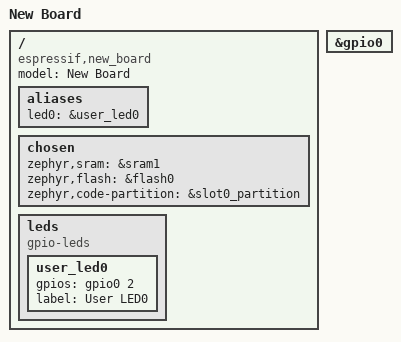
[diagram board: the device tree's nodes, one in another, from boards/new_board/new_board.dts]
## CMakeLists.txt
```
cmake_minimum_required(VERSION 3.20.0)

list(APPEND BOARD_ROOT ${CMAKE_CURRENT_SOURCE_DIR})
find_package(Zephyr REQUIRED)
project(my_zephyr_app)

target_sources(app PRIVATE src/main.cpp)
target_include_directories(app PRIVATE ${CMAKE_CURRENT_SOURCE_DIR}/drivers/our_driver)

add_subdirectory(drivers/our_driver)
```

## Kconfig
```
menuconfig LED_SUBSYSTEM
    bool "LED Subsystem"

    help
      Enable LED subsystem support.

if LED_SUBSYSTEM
    choice 
        prompt "LED Blink sleep"
        default BLINK_SLEEP_1000MS
    
    config BLINK_SLEEP_1000MS
        bool "1s Medium"
    
    config BLINK_SLEEP_250MS
        bool "250ms Very Fast"
    
    config BLINK_SLEEP_2000MS
        bool "2s Slow"
    
    config BLINK_SLEEP_500MS
        bool "500ms Fast"
    
    endchoice

    config BLINK_SLEEP_TIME_MS
        int
        default 1000 if BLINK_SLEEP_1000MS
        default 250 if BLINK_SLEEP_250MS
        default 2000 if BLINK_SLEEP_2000MS
        default 500 if BLINK_SLEEP_500MS
    
menuconfig ADVANCED_LED_SETTINGS
    bool "Advanced LED Settings"

if ADVANCED_LED_SETTINGS    
    config LED_BRIGHTNESS
            int "LED Brightness (0-100)"
            default 100
            range 0 100
        
    config LED_FADE
            int "LED Fade Duration (ms)"
            default 500
            range 0 5000

menu "Expert Settings"
    visible if ADVANCED_LED_SETTINGS

    config LED_DEBUG
        bool "Enable LED Debugging"

    config CUSTOM_BLINK_PATTERN
        bool "Custom Blink Pattern"

endmenu

endif

endif

config APP_HEARTBEAT_PERIOD_MS
    int "Heartbeat LED blink period (milliseconds)"
    default 500
    range 100 2000
    help
      Controls the LED blinking period in milliseconds.
      Range: 100ms (fast blink) to 2000ms (slow blink).
      Default: 500ms

source "Kconfig.zephyr"
rsource "drivers/our_driver/Kconfig"
```

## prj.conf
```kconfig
CONFIG_GPIO=y
CONFIG_SENSOR=y
CONFIG_LOG=y
CONFIG_OUR_DRIVER=y
CONFIG_SHELL=y
CONFIG_ZTEST=y
CONFIG_ZTEST_SHUFFLE=y
```

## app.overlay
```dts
#include <zephyr/dt-bindings/gpio/gpio.h>

/ {
    leds {
        compatible = "gpio-leds";

        user_led0: user_led0 {
            gpios = <&gpio0 2 GPIO_ACTIVE_HIGH>;
            label = "User LED0";
        };
    };

    aliases {
        led0 = &user_led0;
        app-led = &user_led0;
    };

    our_driver0: our_driver {
        compatible = "our,driver";
        status = "okay";
    };
};
```

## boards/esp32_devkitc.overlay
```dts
/*
 * SPDX-License-Identifier: Apache-2.0
 */

/ {
	leds {
		compatible = "gpio-leds";

		user_led0: user_led0 {
			gpios = <&gpio0 2 GPIO_ACTIVE_HIGH>;
			label = "User LED0";
		};
	};

	aliases {
		led0 = &user_led0;
		app-led = &user_led0;
	};
};
```

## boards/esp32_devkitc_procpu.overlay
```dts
/*
 * SPDX-License-Identifier: Apache-2.0
 */

/ {
	leds {
		compatible = "gpio-leds";

		user_led0: user_led0 {
			gpios = <&gpio0 2 GPIO_ACTIVE_HIGH>;
			label = "User LED0";
		};
	};

	aliases {
		app-led = &user_led0;
	};
};
```

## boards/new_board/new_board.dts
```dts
/dts-v1/;

#include <espressif/esp32/esp32_wrover_e_n4r8.dtsi>
#include <zephyr/dt-bindings/input/input-event-codes.h>
#include <zephyr/dt-bindings/input/esp32-touch-sensor-input.h>
#include <espressif/partitions_0x1000_amp.dtsi>

/  {
    model = "New Board";
	compatible = "espressif,new_board";
    
    aliases {
		led0 = &user_led0;
	};

    chosen {
		zephyr,sram = &sram1;
		zephyr,flash = &flash0;
		zephyr,code-partition = &slot0_partition;
	};

    leds {
        compatible = "gpio-leds";

        user_led0: user_led0 {
            gpios = <&gpio0 2 GPIO_ACTIVE_HIGH>;
            label = "User LED0";
        };
    };
};

&gpio0 {
	status = "okay";
};
```

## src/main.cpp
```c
#include <zephyr/kernel.h>
#include <zephyr/logging/log.h>
#include <zephyr/drivers/sensor.h>
#include "our_driver.h"

LOG_MODULE_REGISTER(main, LOG_LEVEL_INF);

int main(void)
{
	const struct device *driver = DEVICE_DT_GET(DT_NODELABEL(our_driver0));
	struct sensor_value val;
	uint32_t cycle = 0U;

	if (!device_is_ready(driver)) {
		LOG_ERR("our_driver0 is not ready");
		return 0;
	}

	int ret = our_driver_set_on_value(driver, 1U);
	if (ret < 0) {
		LOG_ERR("Failed to set custom driver parameter: %d", ret);
		return 0;
	}

	LOG_INF("Blinking LED through our_driver");

	while (1) {
		cycle++;
		if ((cycle % 20U) == 0U) {
			ret = our_driver_set_on_value(driver, 1U);
			LOG_INF("Custom parameter changed: on_value=1");
		} else if ((cycle % 10U) == 0U) {
			ret = our_driver_set_on_value(driver, 0U);
			LOG_INF("Custom parameter changed: on_value=0");
		}

		if (ret < 0) {
			LOG_ERR("Failed to update custom parameter: %d", ret);
			k_msleep(CONFIG_APP_HEARTBEAT_PERIOD_MS);
			continue;
		}

		ret = sensor_sample_fetch(driver);
		if (ret < 0) {
			LOG_ERR("our_driver sample_fetch failed: %d", ret);
			k_msleep(CONFIG_APP_HEARTBEAT_PERIOD_MS);
			continue;
		}

		k_msleep(CONFIG_APP_HEARTBEAT_PERIOD_MS);

		ret = sensor_channel_get(driver, SENSOR_CHAN_ALL, &val);
		if (ret < 0) {
			LOG_ERR("our_driver channel_get failed: %d", ret);
		} else {
			LOG_INF("LED state after channel_get: %d", val.val1);
		}

		k_msleep(CONFIG_APP_HEARTBEAT_PERIOD_MS);
	}

	return 0;
}
```
